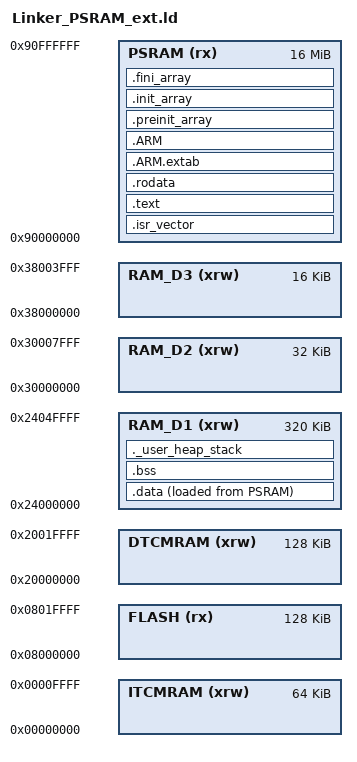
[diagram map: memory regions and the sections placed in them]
/*
******************************************************************************
**  File        : Linker_PSRAM_ext.ld
**  Abstract    : Linker para STM32H730IBT6Q — código en PSRAM @ 0x90000000
**                Datos en RAM_D1 (AXI SRAM) @ 0x24000000
**                Cargado en NOR @ 0x70000000, copiado a PSRAM por Boot App.
****************************************************************************
*/

ENTRY(Reset_Handler)

_estack = ORIGIN(RAM_D1) + LENGTH(RAM_D1);
_Min_Heap_Size = 0x200;
_Min_Stack_Size = 0x2000;

MEMORY
{
  ITCMRAM (xrw) : ORIGIN = 0x00000000, LENGTH = 64K
  DTCMRAM (xrw) : ORIGIN = 0x20000000, LENGTH = 128K
  FLASH   (rx)  : ORIGIN = 0x08000000, LENGTH = 128K
  RAM_D1  (xrw) : ORIGIN = 0x24000000, LENGTH = 320K
  RAM_D2  (xrw) : ORIGIN = 0x30000000, LENGTH = 32K
  RAM_D3  (xrw) : ORIGIN = 0x38000000, LENGTH = 16K
  PSRAM   (rx)  : ORIGIN = 0x90000000, LENGTH = 16M
}

SECTIONS
{
  .isr_vector :
  {
    . = ALIGN(4);
    KEEP(*(.isr_vector))
    . = ALIGN(4);
  } >PSRAM

.text :
  {
    . = ALIGN(8);
    *(.text)
    *(.text*)
    *(.glue_7)
    *(.glue_7t)
    *(.eh_frame)
    KEEP (*(.init))
    KEEP (*(.fini))
    . = ALIGN(8);
    _etext = .;
  } >PSRAM
  
  .rodata :
  {
    . = ALIGN(4);
    *(.rodata)
    *(.rodata*)
    . = ALIGN(4);
  } >PSRAM

  .ARM.extab (READONLY) : { *(.ARM.extab* .gnu.linkonce.armextab.*) } >PSRAM
  .ARM (READONLY) :
  {
    __exidx_start = .;
    *(.ARM.exidx*)
    __exidx_end = .;
  } >PSRAM

  .preinit_array (READONLY) :
  {
    PROVIDE_HIDDEN (__preinit_array_start = .);
    KEEP (*(.preinit_array*))
    PROVIDE_HIDDEN (__preinit_array_end = .);
  } >PSRAM

  .init_array (READONLY) :
  {
    PROVIDE_HIDDEN (__init_array_start = .);
    KEEP (*(SORT(.init_array.*)))
    KEEP (*(.init_array*))
    PROVIDE_HIDDEN (__init_array_end = .);
  } >PSRAM

  .fini_array (READONLY) :
  {
    PROVIDE_HIDDEN (__fini_array_start = .);
    KEEP (*(SORT(.fini_array.*)))
    KEEP (*(.fini_array*))
    PROVIDE_HIDDEN (__fini_array_end = .);
  } >PSRAM

  _sidata = LOADADDR(.data);


.data :
  {
    . = ALIGN(8);
    _sdata = .;
    *(.data)
    *(.data*)
    *(.RamFunc)
    *(.RamFunc*)
    . = ALIGN(8);
    _edata = .;
  } >RAM_D1 AT> PSRAM

. = ALIGN(8);                   /* CAMBIO: era ALIGN(4) */
  .bss :
  {
    . = ALIGN(8);                 /* CAMBIO */
    _sbss = .;
    __bss_start__ = _sbss;
    *(.bss)
    *(.bss*)
    *(COMMON)
    . = ALIGN(8);                 /* CAMBIO: era ALIGN(4) */
    _ebss = .;
    __bss_end__ = _ebss;
  } >RAM_D1

  ._user_heap_stack :
  {
    . = ALIGN(8);
    PROVIDE ( end = . );
    PROVIDE ( _end = . );
    . = . + _Min_Heap_Size;
    . = . + _Min_Stack_Size;
    . = ALIGN(8);
  } >RAM_D1


  .ARM.attributes 0 : { *(.ARM.attributes) }
}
